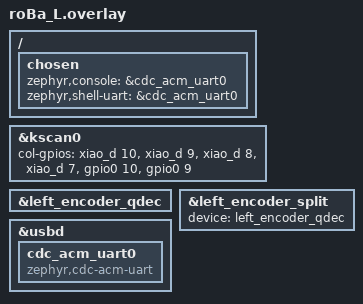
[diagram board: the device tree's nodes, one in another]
#include "roBa.dtsi"

&kscan0 {
        col-gpios
            = <&xiao_d 10 GPIO_ACTIVE_HIGH>
            , <&xiao_d 9 GPIO_ACTIVE_HIGH> 
            , <&xiao_d 8 GPIO_ACTIVE_HIGH> 
            , <&xiao_d 7 GPIO_ACTIVE_HIGH> 
            , <&gpio0 10 GPIO_ACTIVE_HIGH>
            , <&gpio0 9 GPIO_ACTIVE_HIGH>
            ;
};

&left_encoder_qdec {
    status = "okay";
};

&left_encoder_split {
    device = <&left_encoder_qdec>;
    // 回転方向が逆に感じたら、上の gpio-qdec ノードの
    // gpios = <...>, <...>; の2つの並びを入れ替えるか、
    // ここに input-processors = <&zip_scroll_transform (INPUT_TRANSFORM_Y_INVERT)>;
    // を追加する。
};

// USBデバッグログ(roBa_L_with_logging ビルド)用。
// seeeduino_xiao_ble のボード定義にはCDC ACM(仮想シリアル)ノードが
// 含まれていないため、CONFIG_ZMK_USB_LOGGING を有効にするにはここで
// 追加しておく必要がある。通常ビルドでは未使用のノードが増えるだけで
// 影響はない。
/ {
    chosen {
        zephyr,console = &cdc_acm_uart0;
        zephyr,shell-uart = &cdc_acm_uart0;
    };
};

&usbd {
    cdc_acm_uart0: cdc_acm_uart0 {
        compatible = "zephyr,cdc-acm-uart";
    };
};
